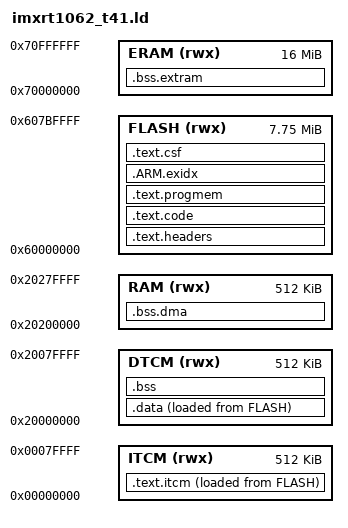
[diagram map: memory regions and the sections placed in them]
MEMORY
{
	ITCM (rwx):  ORIGIN = 0x00000000, LENGTH = 512K
	DTCM (rwx):  ORIGIN = 0x20000000, LENGTH = 512K
	RAM (rwx):   ORIGIN = 0x20200000, LENGTH = 512K
	FLASH (rwx): ORIGIN = 0x60000000, LENGTH = 7936K
	ERAM (rwx):  ORIGIN = 0x70000000, LENGTH = 16384K
}

ENTRY(ImageVectorTable)

SECTIONS
{
	.text.headers : {
		KEEP(*(.flag_CONFIG))
		FILL(0xFF)
		. = ORIGIN(FLASH) + 0x1000;
		KEEP(*(.ivt))
		KEEP(*(.boot_data))
		. = ALIGN(1024);
	} > FLASH

	.text.code : {
		KEEP(*(.startup))
		*(.flashmem*)
		. = ALIGN(4);
		KEEP(*(.init))
		__preinit_array_start = .;
		KEEP (*(.preinit_array))
		__preinit_array_end = .;
		__init_array_start = .;
		KEEP (*(.init_array))
		__init_array_end = .;
		. = ALIGN(4);
	} > FLASH

	.text.progmem : {
		*(.progmem*)
		. = ALIGN(4);
	} > FLASH

	.text.itcm : {
		. = . + 32; /* MPU to trap NULL pointer deref */
		*(.fastrun)
		*(.text*)
		. = ALIGN(16);
	} > ITCM  AT> FLASH

	.ARM.exidx : {
		__exidx_start = .;
		*(.ARM.exidx* .ARM.extab.text* .gnu.linkonce.armexidx.*)
		__exidx_end = .;
	} > FLASH

	.data : {
		*(.endpoint_queue)   
		*(SORT_BY_ALIGNMENT(SORT_BY_NAME(.rodata*)))
		*(SORT_BY_ALIGNMENT(SORT_BY_NAME(.data*)))
		KEEP(*(.vectorsram))
	} > DTCM AT> FLASH

	.bss ALIGN(4) : {
		*(SORT_BY_ALIGNMENT(SORT_BY_NAME(.bss*)))
		*(SORT_BY_ALIGNMENT(SORT_BY_NAME(COMMON)))
		. = ALIGN(32);
		. = . + 32; /* MPU to trap stack overflow */
		__stack_bottom = .;
	} > DTCM

	.bss.dma (NOLOAD) : {
		*(.hab_log)
		*(.dmabuffers)
		. = ALIGN(32);
	} > RAM

	.bss.extram (NOLOAD) : {
		*(SORT_BY_ALIGNMENT(SORT_BY_NAME(.externalram)))
		. = ALIGN(32);
	} > ERAM

	.text.csf : {
		FILL(0xFF)
		. = ALIGN(1024);
		KEEP(*(.csf))
		__text_csf_end = .;
	} > FLASH

	_itcm_text_start = ADDR(.text.itcm);
	_itcm_text_end = ADDR(.text.itcm) + SIZEOF(.text.itcm)
	_itcm_text_load_start = LOADADDR(.text.itcm);

	_data_start = ADDR(.data);
	_data_end = ADDR(.data) + SIZEOF(.data);
	_data_load_start = LOADADDR(.data);

	_bss_start = ADDR(.bss);
	_bss_end = ADDR(.bss) + SIZEOF(.bss);

	_heap_start = ADDR(.bss.dma) + SIZEOF(.bss.dma);
	_heap_end = ORIGIN(RAM) + LENGTH(RAM);

	_extram_start = ADDR(.bss.extram);
	_extram_end = ADDR(.bss.extram) + SIZEOF(.bss.extram);

	_itcm_block_count = (SIZEOF(.text.itcm) + SIZEOF(.ARM.exidx) + 0x7FFF) >> 15;
	_flexram_bank_config = 0xAAAAAAAA | ((1 << (_itcm_block_count * 2)) - 1);
	_stack_top = ORIGIN(DTCM) + ((16 - _itcm_block_count) << 15);

	_flash_image_len = __text_csf_end - ORIGIN(FLASH);
	_teensy_model_identifier = 0x25;

	/* DWARF debug sections.
	* Symbols in the DWARF debugging sections are relative to the beginning
	* of the section so we begin them at 0.  */
	.debug_info     0 : { *(.debug_info) }
	.debug_abbrev   0 : { *(.debug_abbrev) }
	.debug_line     0 : { *(.debug_line) }
	.debug_frame    0 : { *(.debug_frame) }
	.debug_str      0 : { *(.debug_str) }
	.debug_loc      0 : { *(.debug_loc) }
}
